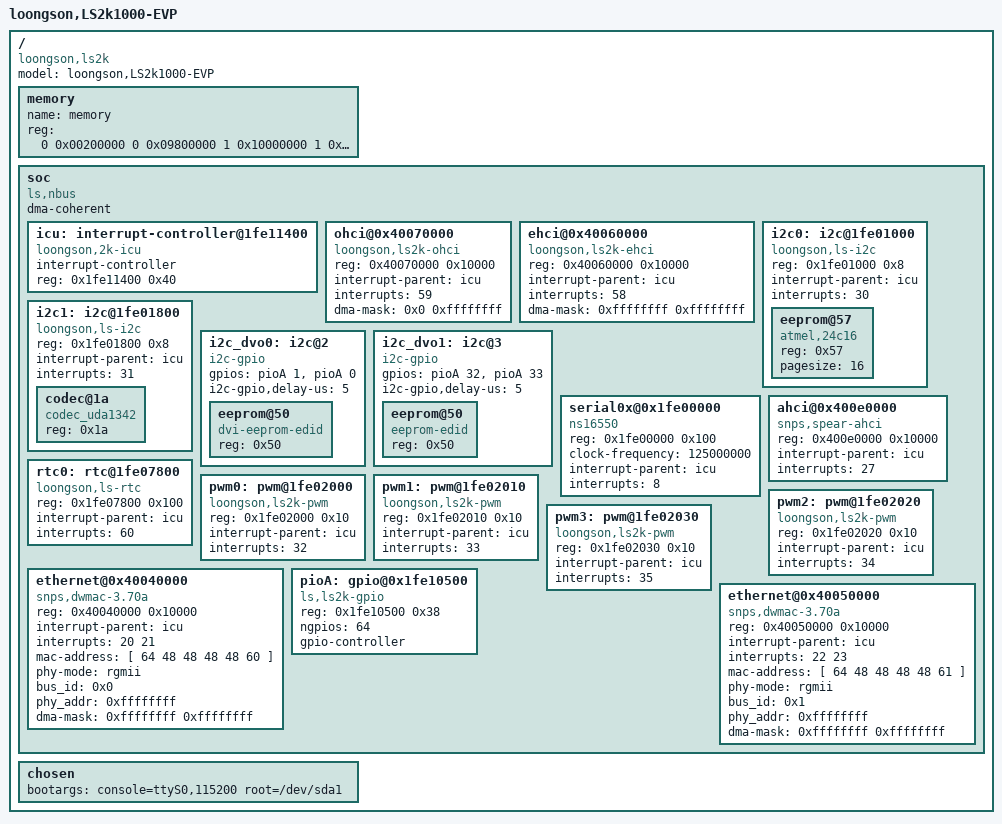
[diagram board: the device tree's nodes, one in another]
/*
 * 2K1000 Device Tree Source for LS2K1000 boards
 */

/dts-v1/;
/ {
	model = "loongson,LS2k1000-EVP";
	compatible = "loongson,ls2k";
	#address-cells = <2>;
	#size-cells = <2>;

	// Since 2K1000 support > 4GiB DIMM, use 2 cell for and address size
	memory {
		name = "memory";
		device_type = "memory";
		reg =  <0 0x00200000 0 0x09800000	// 216MiB at 2MiB
			1 0x10000000 1 0xb0000000>;	// 7424 - 512 MiB at 4352MiB
	};

	// all soc device use 32bit address

	soc {
		compatible = "ls,nbus", "simple-bus";
		#address-cells = <1>;
		#size-cells = <1>;
		ranges = <0x10000000 0 0x10000000 0x10000000
			  0x40000000 0 0x40000000 0x40000000
			  0x20000000 0 0x20000000 0x20000000
			  0x0d000000 0 0x0d000000 0x02000000>;

		dma-coherent;

		icu: interrupt-controller@1fe11400 {
			compatible = "loongson,2k-icu";
			interrupt-controller;
			#interrupt-cells = <1>;
			reg = <0x1fe11400 0x40>;
		};

		ohci@0x40070000 {
			compatible = "loongson,ls2k-ohci", "usb-ohci";
			reg = <0x40070000 0x10000>;
			interrupt-parent = <&icu>;
			interrupts = <59>;
			dma-mask = <0x0 0xffffffff>;
		};

		ehci@0x40060000 {
			compatible = "loongson,ls2k-ehci", "usb-ehci";
			reg = <0x40060000 0x10000>;
			interrupt-parent = <&icu>;
			interrupts = <58>;
			dma-mask = <0xffffffff 0xffffffff>;
		};

		i2c0: i2c@1fe01000{
			compatible = "loongson,ls-i2c";
			reg = <0x1fe01000 0x8>;
			interrupt-parent = <&icu>;
			interrupts = <30>;
			#address-cells = <1>;
			#size-cells = <0>;
			eeprom@57{
				compatible = "atmel,24c16";
				reg = <0x57>;
				pagesize = <16>;
			};
		};

		i2c1: i2c@1fe01800{
			#address-cells = <1>;
			#size-cells = <0>;

			compatible = "loongson,ls-i2c";
			reg = <0x1fe01800 0x8>;
			interrupt-parent = <&icu>;
			interrupts = <31>;
			codec@1a{
				compatible = "codec_uda1342";
				reg = <0x1a>;
			};
		};

		i2c_dvo0:i2c@2{
			compatible = "i2c-gpio";
			gpios = <&pioA 1 0 /* sda */
				 &pioA 0 0 /* scl */
				>;
			/*i2c-gpio,sda-open-drain;*/
			/*i2c-gpio,scl-open-drain;*/
			i2c-gpio,delay-us = <5>;	/* ~100 kHz */
			#address-cells = <1>;
			#size-cells = <0>;
			eeprom@50{
				compatible = "dvi-eeprom-edid";
				reg = <0x50>;
			};
		};

		i2c_dvo1:i2c@3{
			compatible = "i2c-gpio";
			gpios = <&pioA 32 0 /* sda */
				 &pioA 33 0 /* scl */
				>;
			/*i2c-gpio,sda-open-drain;*/
			/*i2c-gpio,scl-open-drain;*/
			i2c-gpio,delay-us = <5>;	/* ~100 kHz */
			#address-cells = <1>;
			#size-cells = <0>;
			eeprom@50{
				compatible = "eeprom-edid";
				reg = <0x50>;
			};
		};

		serial0x@0x1fe00000{
			device_type = "serial";
			compatible = "ns16550";
			reg = <0x1fe00000 0x100>;
			clock-frequency = <125000000>;
			interrupt-parent = <&icu>;
			interrupts = <8>;
		};

		ahci@0x400e0000{
			compatible = "snps,spear-ahci";
			reg = <0x400e0000 0x10000>;
			interrupt-parent = <&icu>;
			interrupts = <27>;
		};

		rtc0: rtc@1fe07800{
			compatible = "loongson,ls-rtc";
			reg = <0x1fe07800 0x100>;
			interrupt-parent = <&icu>;
			interrupts = <60>;
		};

		pwm0: pwm@1fe02000{
			compatible = "loongson,ls2k-pwm";
			reg = <0x1fe02000 0x10>;
			interrupt-parent = <&icu>;
			interrupts = <32>;
		};

		pwm1: pwm@1fe02010{
			compatible = "loongson,ls2k-pwm";
			reg = <0x1fe02010 0x10>;
			interrupt-parent = <&icu>;
			interrupts = <33>;
		};

		pwm2: pwm@1fe02020{
			compatible = "loongson,ls2k-pwm";
			reg = <0x1fe02020 0x10>;
			interrupt-parent = <&icu>;
			interrupts = <34>;
		};

		pwm3: pwm@1fe02030{
			compatible = "loongson,ls2k-pwm";
			reg = <0x1fe02030 0x10>;
			interrupt-parent = <&icu>;
			interrupts = <35>;
		};

		ethernet@0x40040000 {
			compatible = "snps,dwmac-3.70a", "ls,ls-gmac";
			reg = <0x40040000 0x10000>;
			interrupt-parent = <&icu>;
			interrupts = <20 21>;
			interrupt-names = "macirq", "eth_wake_irq";
			mac-address = [ 64 48 48 48 48 60 ];
			phy-mode = "rgmii";
			bus_id = <0x0>;
			phy_addr = <0xffffffff>;
			dma-mask = <0xffffffff 0xffffffff>;
		};

		ethernet@0x40050000 {
			compatible = "snps,dwmac-3.70a", "ls,ls-gmac";
			reg = <0x40050000 0x10000>;
			interrupt-parent = <&icu>;
			interrupts = <22 23>;
			interrupt-names = "macirq", "eth_wake_irq";
			mac-address = [ 64 48 48 48 48 61 ];
			phy-mode = "rgmii";
			bus_id = <0x1>;
			phy_addr = <0xffffffff>;
			dma-mask = <0xffffffff 0xffffffff>;
		};
		pioA:gpio@0x1fe10500{
			compatible = "ls,ls2k-gpio", "ls,ls-gpio";
			reg = <0x1fe10500 0x38>;
			ngpios = <64>;
			gpio-controller;
			#gpio-cells = <2>;
		};

	};

	chosen {
		bootargs = "console=ttyS0,115200 root=/dev/sda1 ";
	};
};
